# LargeDummyDevice register map
File version: 1.0
Registers are 32-bit, read-write, no defined reset value unless marked. A register's access mark holds for its fields unless they carry their own. Offsets are from the block's base; [hi:lo] are bit positions.

## PERIPHERAL_22
Base 0x40015000
0x04 REG_1 — Register 1
  [32:29] FIELD_16, [29:28] FIELD_14, [28:26] FIELD_4, [27:26] FIELD_8, [27:25] FIELD_18, [27:24] FIELD_1, [27:24] FIELD_5, [27:23] FIELD_10, [21] FIELD_9, [21:20] FIELD_13, [21:19] FIELD_12, [15:14] FIELD_2, [11:10] FIELD_7, [9] FIELD_6, [9:8] FIELD_11, [7:4] FIELD_17, [4:2] FIELD_15, [1] FIELD_3
0x08 REG_2 — Register 2
  [34:31] FIELD_2, [32:31] FIELD_3, [31] FIELD_9, [35:31] FIELD_27, [30] FIELD_12, [31:29] FIELD_4, [30:28] FIELD_15, [28:27] FIELD_24, [30:26] FIELD_10, [27:26] FIELD_16, [30:26] FIELD_25, [26] FIELD_28, [26:24] FIELD_13, [25:23] FIELD_23, [23:22] FIELD_7, [18] FIELD_14, [16:15] FIELD_20, [17:15] FIELD_22, [15] FIELD_30, [16:14] FIELD_19, [15:13] FIELD_17, [16:12] FIELD_29, [12:8] FIELD_6, [8:7] FIELD_18, [7] FIELD_26, [9:6] FIELD_8, [6:4] FIELD_5, [4:1] FIELD_1, [3:1] FIELD_21, [3:0] FIELD_11, [3:0] FIELD_31
0x0C REG_3 — Register 3
  [31:30] FIELD_11, [29] FIELD_9, [27:26] FIELD_2, [23:20] FIELD_5, [21:17] FIELD_1, [17:13] FIELD_7, [15:12] FIELD_4, [10:9] FIELD_8, [11:8] FIELD_6, [10:7] FIELD_10, [5:4] FIELD_3, [3:2] FIELD_12
0x10 REG_4 — Register 4
  [35:31] FIELD_23, [30] FIELD_11, [32:30] FIELD_27, [31:28] FIELD_9, [28] FIELD_29, [28] FIELD_32, [29:27] FIELD_6, [31:27] FIELD_10, [29:27] FIELD_15, [26] FIELD_22, [24] FIELD_28, [27:23] FIELD_14, [22] FIELD_18, [25:22] FIELD_19, [24:21] FIELD_31, [20:19] FIELD_30, [18:17] FIELD_17, [15] FIELD_3, [15] FIELD_7, [14:13] FIELD_8, [13:11] FIELD_24, [11:10] FIELD_2, [10] FIELD_5, [8] FIELD_20, [11:7] FIELD_12, [8:7] FIELD_26, [8:4] FIELD_4, [7:4] FIELD_16, [3:2] FIELD_1, [5:2] FIELD_21, [1] FIELD_25, [0] FIELD_13
0x14 REG_5 — Register 5
  [30] FIELD_7, [30:26] FIELD_6, [20:19] FIELD_4, [20:17] FIELD_1, [16:14] FIELD_2, [14:12] FIELD_3, [11:7] FIELD_5, [9:5] FIELD_8
0x18 REG_6 — Register 6
  [31] FIELD_10, [31:30] FIELD_5, [29] FIELD_8, [32:29] FIELD_15, [27:26] FIELD_4, [28:26] FIELD_7, [25:22] FIELD_6, [21:19] FIELD_12, [19:18] FIELD_16, [20:17] FIELD_1, [21:17] FIELD_2, [20:17] FIELD_3, [14] FIELD_11, [16:13] FIELD_13, [12:8] FIELD_9, [8] FIELD_17, [3:2] FIELD_14
0x1C REG_7 — Register 7
  [25:23] FIELD_4, [12] FIELD_2, [9:7] FIELD_1, [7:5] FIELD_5, [4:3] FIELD_3
0x20 REG_8 — Register 8
  [30] FIELD_1, [33:29] FIELD_3, [26:23] FIELD_5, [25:21] FIELD_2, [20] FIELD_4, [21:18] FIELD_6, [22:18] FIELD_9, [20:16] FIELD_7, [4:2] FIELD_8
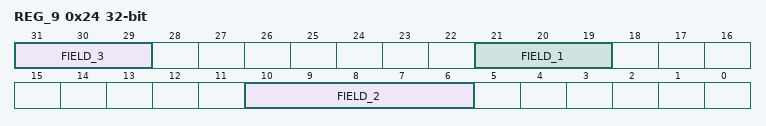
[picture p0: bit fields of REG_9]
0x24 REG_9 — Register 9
  [31:29] FIELD_3, [21:19] FIELD_1, [10:6] FIELD_2
0x28 REG_10 — Register 10
  [33:30] FIELD_20, [32:29] FIELD_19, [27] FIELD_3, [26] FIELD_7, [26:25] FIELD_23, [23:22] FIELD_21, [24:21] FIELD_12, [20] FIELD_15, [16:15] FIELD_4, [14:13] FIELD_1, [16:13] FIELD_8, [13] FIELD_10, [12] FIELD_6, [16:12] FIELD_22, [7:6] FIELD_18, [8:5] FIELD_9, [8:5] FIELD_14, [5] FIELD_17, [6:4] FIELD_5, [3] FIELD_2, [3:2] FIELD_11, [2:1] FIELD_16, [2:0] FIELD_13
0x2C REG_11 — Register 11
  [22] FIELD_2, [22] FIELD_4, [19:16] FIELD_5, [8:6] FIELD_1, [4:0] FIELD_3
0x30 REG_12 — Register 12
  [34:30] FIELD_9, [32:28] FIELD_1, [31:28] FIELD_11, [32:28] FIELD_14, [28:25] FIELD_3, [25] FIELD_4, [24:21] FIELD_10, [24:21] FIELD_16, [20] FIELD_12, [18:16] FIELD_6, [15] FIELD_20, [18:14] FIELD_5, [14:11] FIELD_7, [13:11] FIELD_13, [14:11] FIELD_18, [10] FIELD_8, [10:8] FIELD_19, [4] FIELD_21, [5:3] FIELD_17, [3:2] FIELD_2, [4:0] FIELD_15
0x34 REG_13 — Register 13
  [32:28] FIELD_18, [28:27] FIELD_3, [26] FIELD_11, [29:25] FIELD_4, [26:22] FIELD_13, [18:15] FIELD_19, [14:12] FIELD_14, [15:11] FIELD_2, [12:11] FIELD_12, [14:10] FIELD_8, [12:10] FIELD_15, [10] FIELD_17, [12:9] FIELD_6, [12:9] FIELD_9, [9] FIELD_16, [12:8] FIELD_7, [6:2] FIELD_10, [3:1] FIELD_1, [2:0] FIELD_5
0x38 REG_14 — Register 14
  [35:31] FIELD_6, [26] FIELD_4, [26] FIELD_8, [22:20] FIELD_16, [23:19] FIELD_12, [19:17] FIELD_10, [18:14] FIELD_14, [15:12] FIELD_15, [12:10] FIELD_1, [13:9] FIELD_2, [9:8] FIELD_3, [9:8] FIELD_5, [6:5] FIELD_11, [7:4] FIELD_9, [5:2] FIELD_7, [2:0] FIELD_13
0x3C REG_15 — Register 15
  [30:28] FIELD_3, [31:28] FIELD_17, [27:26] FIELD_4, [29:26] FIELD_8, [28:26] FIELD_14, [24] FIELD_12, [27:23] FIELD_10, [27:23] FIELD_18, [22] FIELD_2, [25:21] FIELD_6, [22:21] FIELD_11, [23:19] FIELD_22, [22:18] FIELD_19, [19:18] FIELD_20, [20:16] FIELD_16, [17:13] FIELD_13, [12:9] FIELD_1, [8:6] FIELD_21, [5] FIELD_15, [7:4] FIELD_7, [4] FIELD_9, [6:3] FIELD_5, [4:2] FIELD_23
